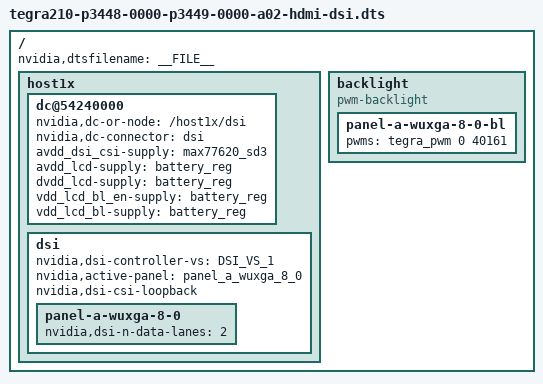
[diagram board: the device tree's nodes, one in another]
/*
 * arch/arm64/boot/dts/tegra210-p3448-0000-p3449-0000-b00-hdmi-dsi.dts
 *
 * Copyright (c) 2019, NVIDIA CORPORATION.  All rights reserved.
 *
 * This program is free software; you can redistribute it and/or modify
 * it under the terms of the GNU General Public License as published by
 * the Free Software Foundation; version 2 of the License.
 *
 * This program is distributed in the hope that it will be useful, but WITHOUT
 * ANY WARRANTY; without even the implied warranty of MERCHANTABILITY or
 * FITNESS FOR A PARTICULAR PURPOSE.  See the GNU General Public License for
 * more details.
 *
 * You should have received a copy of the GNU General Public License along
 * with this program; if not, write to the Free Software Foundation, Inc.,
 * 51 Franklin Street, Fifth Floor, Boston, MA  02110-1301, USA.
 *
 */

#include "tegra210-p3448-0000-p3449-0000-a02.dts"
#include <panels/panel-a-wuxga-8-0.dtsi>

/ {
	nvidia,dtsfilename = __FILE__;
	host1x {
		/* DSI mapped to tegradc.1 */
		dc@54240000 {
			status = "okay";
			nvidia,dc-or-node = "/host1x/dsi";
			nvidia,dc-connector = <&dsi>;
			/* DSI supplies */
			avdd_dsi_csi-supply = <&max77620_sd3>;
			avdd_lcd-supply = <&battery_reg>;
			dvdd_lcd-supply = <&battery_reg>;
			vdd_lcd_bl_en-supply = <&battery_reg>;
			vdd_lcd_bl-supply = <&battery_reg>;
		};

		dsi {
			nvidia,dsi-controller-vs = <DSI_VS_1>;
			status = "okay";
			nvidia,active-panel = <&panel_a_wuxga_8_0>;
			nvidia,dsi-csi-loopback;
			panel-a-wuxga-8-0 {
				status = "okay";
				/* Only 2 lanes used on Porg */
				nvidia,dsi-n-data-lanes = <2>;
			};
		};
	};

	backlight {
		compatible = "pwm-backlight";
		status = "okay";
		panel-a-wuxga-8-0-bl {
			status = "okay";
			pwms = <&tegra_pwm 0 40161>;
		};
	};
};
